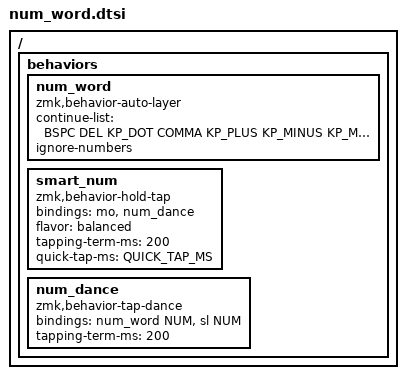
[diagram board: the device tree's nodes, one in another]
#include <dt-bindings/zmk/behaviors.h>
#include <dt-bindings/zmk/keys.h>

/ {
    behaviors {
        num_word: num_word {
            compatible = "zmk,behavior-auto-layer";
            #binding-cells = <1>;
            continue-list = <BSPC DEL KP_DOT COMMA KP_PLUS KP_MINUS KP_MULTIPLY KP_DIVIDE KP_EQUAL DLLR>;
            ignore-numbers;
        };
    };
};

// Tap: num-word | double-tap: sticky num-layer | Hold: num-layer.
#define SMART_NUM &smart_num NUM 0
ZMK_HOLD_TAP(smart_num, bindings = <&mo>, <&num_dance>; flavor = "balanced";
             tapping-term-ms = <200>; quick-tap-ms = <QUICK_TAP_MS>;)
ZMK_TAP_DANCE(num_dance, bindings = <&num_word NUM>, <&sl NUM>;
              tapping-term-ms = <200>;)
